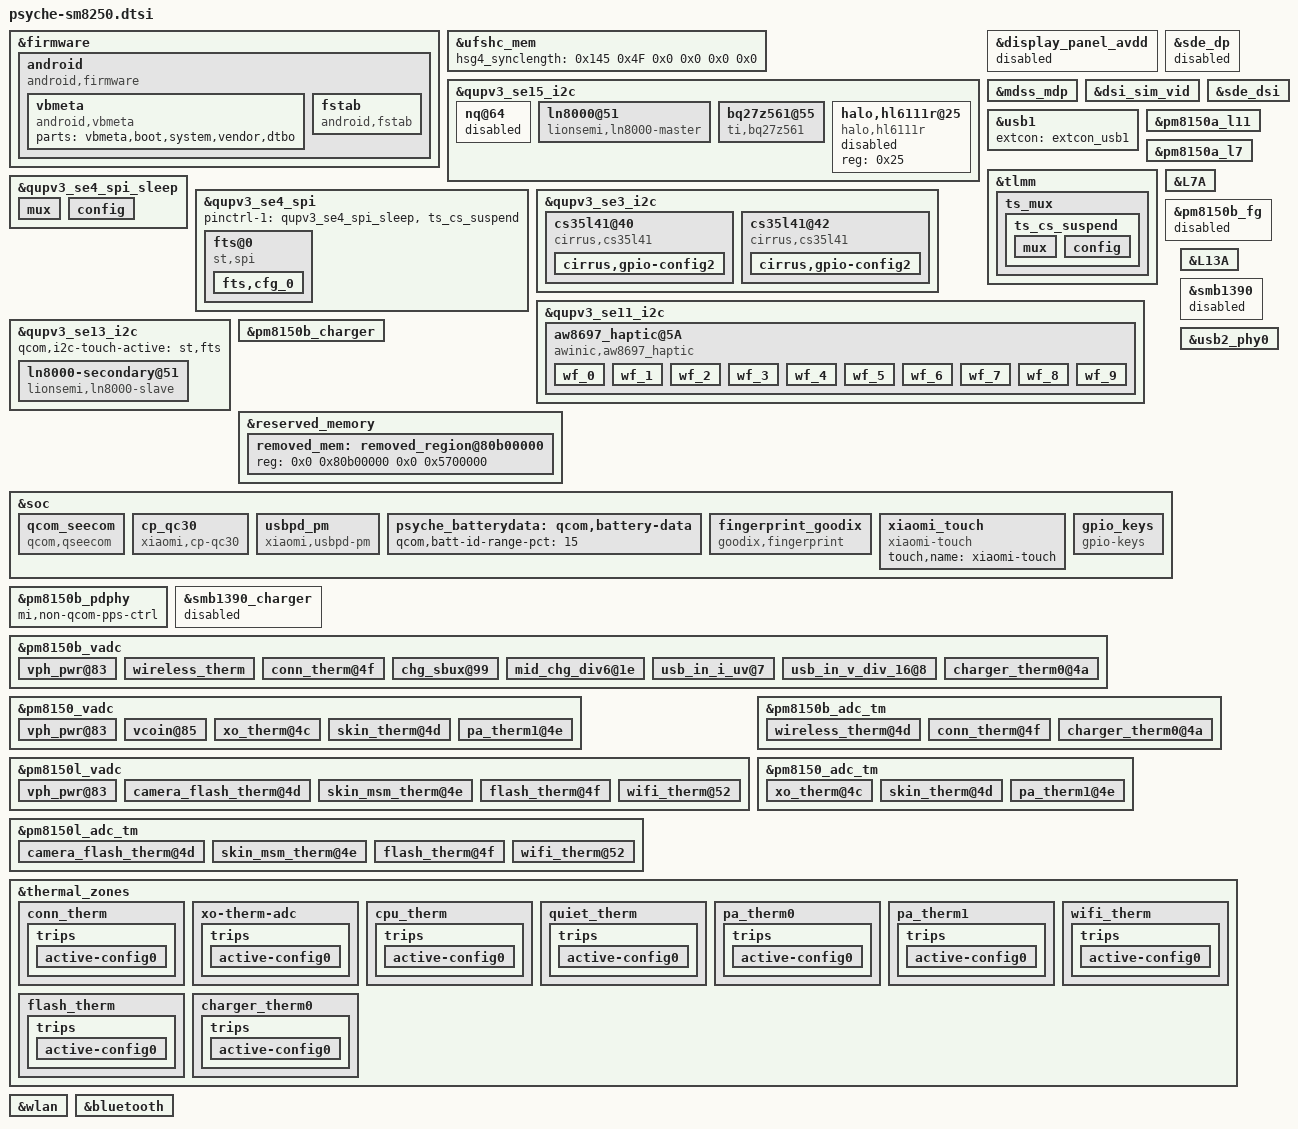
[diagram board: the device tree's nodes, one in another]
/*
this file is for attribution only of psyche
And public attribution of xiaomi platforms(like L3A and so and)
*/

#include "psyche-pinctrl.dtsi"
#include "xiaomi-sm8250-common.dtsi"
#include "psyche-audio-overlay.dtsi"

&firmware {
	android {
		compatible = "android,firmware";
		vbmeta {
			compatible = "android,vbmeta";
			parts = "vbmeta,boot,system,vendor,dtbo";
		};

		fstab {
			compatible = "android,fstab";
		};
	};
};
&ufshc_mem {
	hsg4_synclength = /bits/ 16 <0x145 0x4F
				     0x0 0x0
				     0x0 0x0>;
};

&qupv3_se15_i2c {
	status = "ok";
	nq@64 {
		status = "disabled";
	};
};

&display_panel_avdd {
	status = "disabled";
};

&sde_dp {
	status = "disabled";
};

&mdss_mdp {
	connectors = <&sde_wb &sde_dsi &sde_dsi1 &sde_rscc>;
};

&dsi_sim_vid {
	qcom,panel-supply-entries = <&dsi_panel_pwr_supply_vci>;
	qcom,platform-reset-gpio = <&tlmm 12 0>;
};

&usb1 {
        extcon = <&extcon_usb1>;
};

&sde_dsi {
	/delete-property/ vdd-supply;
	/delete-property/ avdd-supply;
	qcom,dsi-default-panel = <&dsi_sim_vid>;
	vci-supply = <&pm8150a_l11>;
};

&pm8150a_l11 {
	qcom,init-voltage = <3000000>;
	regulator-min-microvolt = <3000000>;
	regulator-max-microvolt = <3000000>;
};

&pm8150a_l7 {
	qcom,init-voltage = <3008000>;
	regulator-min-microvolt = <3008000>;
	regulator-max-microvolt = <3008000>;
	regulator-always-on;
};

&qupv3_se15_i2c {
	#address-cells = <1>;
	#size-cells = <0>;
	status = "ok";

	ln8000@51 {
		compatible = "lionsemi,ln8000-master";
		reg = <0x51>;
		/* bank <bit-idx> <flags: active-low> */
		//irq-gpios = <&tlmm 55 0x2002>;
		pinctrl-names = "bq2597x_master_irq";
		pinctrl-0 = <&bq2597x_master_int_default &bq2597x_master_int_suspend>;

		charger_name = "tertiary_chg";

		interrupt-parent = <&tlmm>;
		interrupts = <68 0x2002>;

		//interrupt-parent = <&tlmm>;
		//interrupts = <55 0x2002>;
		//pinctrl-names = "default";
		//pinctrl-0 = <&bq2597x_int_default &bq2597x_int_suspend>;
		//ln8000_charger,irq_index = <296>;

		ln8000_charger,standalone-mode-master;
		/* device configuration */
		ln8000_charger,bat-ovp-threshold = <4710>;
		ln8000_charger,bat-ovp-alarm-threshold = <4675>;
		ln8000_charger,bus-ovp-threshold = <13000>;
		ln8000_charger,bus-ovp-alarm-threshold = <11000>;
		ln8000_charger,bus-ocp-threshold = <3750>;
		ln8000_charger,bus-ocp-alarm-threshold = <3500>;
		ln8000_charger,ntc-alarm-cfg  = <226>;
		/* protection enable/disable flags
		 *   vbat-ovp-disable
		 *   vbat-reg-disable
		 *   iin-ocp-disable
		 *   iin-reg-disable
		 *   tbus-mon-disable
		 *   tbat-mon-disable
		 *   tdie-prot-disable
		 *   tdie-reg-disable
		 *   revcurr-prot-disable
		 */
		ln8000_charger,tdie-prot-disable;
		ln8000_charger,tbus-mon-disable;
		ln8000_charger,tbat-mon-disable;
		ln8000_charger,iin-ocp-disable;
		ln8000_charger,iin-reg-disable;
		ln8000_charger,tdie-reg-disable;
		ln8000_charger,vbat-reg-disable;
	};

	bq27z561@55 {
		compatible = "ti,bq27z561";
		reg = <0x55>;
		bq,ignore-digest-debug;
		bq,charge-full-design = <4500000>;
		bq,recharge-voltage   = <4430>;
		bq,shutdown-delay-enable;
		bq,soc_decimal_rate = <
			0  38
			10 35
			20 33
			30 33
			40 33
			50 33
			60 33
			70 30
			80 25
			90 20
			95 10 >;
		bq,cold_thermal_seq = <
			1      0  100 1700
			2  (-300)   0 1000 >;
	};

	halo,hl6111r@25 {
		compatible = "halo,hl6111r";
		reg = <0x25>;
		status = "disabled";
	};
};
&tlmm {
	ts_mux {
		ts_cs_suspend: ts_cs_suspend {
			mux {
				pins = "gpio11";
				function = "gpio";
			};

			config {
				pins = "gpio11";
				drive-strength = <6>;
				bias-pull-up;
			};
		};
	};
};

&qupv3_se4_spi_sleep {
	mux {
		pins = "gpio8", "gpio9", "gpio10";
		function = "gpio";
	};

	config {
		pins = "gpio8", "gpio9", "gpio10";
		drive-strength = <6>;
		bias-pull-down;
	};
};

&L7A {
	regulator-min-microvolt = <1800000>;
	regulator-max-microvolt = <1800000>;
	qcom,init-voltage = <1800000>;
};

&qupv3_se4_spi {
	status = "ok";
	pinctrl-1 = <&qupv3_se4_spi_sleep &ts_cs_suspend>;
	fts@0 {
		status = "ok";
		compatible = "st,spi";
		reg = <0x0>;
		interrupt-parent = <&tlmm>;
		interrupts = <39 0x2008>;
		pinctrl-names = "pmx_ts_active", "pmx_ts_suspend";
		pinctrl-0 = <&mi_ts_active>;
		pinctrl-1 = <&ts_int_suspend &ts_reset_suspend>;
		avdd-supply = <&L10C>;
		vdd-supply = <&L7A>;
		/*panel = <&dsi_k8_42_02_0a_dsc_cmd>;*/
		fts,pwr-reg-name = "avdd";
		fts,bus-reg-name = "vdd";
		fts,irq-gpio = <&tlmm 39 0x2008>;
		fts,irq-gpio-name = "fts_irq";
		fts,reset-gpio-enable;
		fts,reset-gpio = <&tlmm 33 0x00>;
		fts,reset-gpio-name = "fts_rst";
		fts,irq-flags = <0x2008>;
		fts,x-max = <10800>;
		fts,y-max = <24000>;
		fts,fod-lx = <4330>;
		fts,fod-ly = <20560>;
		fts,fod-x-size = <2140>;
		fts,fod-y-size = <2140>;
		fts,support-fod;
		fts,support-super-resolution = <1>;
		spi-max-frequency = <8000000>;
		fts,default-fw-name = "st_fts_l3a.ftb";
		fts,htp-fw-name = "st_fts_l3a_htp.ftb";
		fts,config-array-size = <1>;
		fts,touch-follow-performance-def = <3>;
		fts,touch-tap-sensitivity-def = <4>;
		fts,touch-aim-sensitivity-def = <3>;
		fts,touch-tap-stability-def = <3>;
		fts,cornerfilter-area-step1 = <100>;
		fts,cornerfilter-area-step2 = <170>;
		fts,cornerfilter-area-step3 = <250>;
		fts,touch-deadzone-filter-ver = <2 0 0 0 0 0 0 0
										2 1 0 0 0 0 0 0
										2 2 0   0 0    2399 0 0
										2 3 1079 0 1079 2399 0 0>;
		fts,touch-deadzone-filter-hor = <2 0 0 0 1079 0 0 0
										2 1 0    2399 1079 2399 0 0
										2 2 0    0    0    2399 0 0
										2 3 1079 0    1079 2399 0 0>;
		fts,touch-edgezone-filter-ver = <1 0 0 0 0 0 0 0
										1 1 0 0 0 0 0 0
										1 2 0    0 60   2339 0 0
										1 3 1019 0 1079 2339 0 0>;
		fts,touch-edgezone-filter-hor = <1 0 0 0 1079 60 0 0
										1 1 0    2339 1079 2399 0 0
										1 2 0    0    60   2399 0 0
										1 3 1019 0    1079 2399 0 0>;
		fts,touch-cornerzone-filter-ver = <0 0 0 0 0 0 0 0
										0 1 0 0 0 0 0 0
										0 2 0 2099 150 2399 0 0
										0 3 929 2099 1079 2399 0 0>;
		fts,touch-cornerzone-filter-hor1 = <0 0 0 0 170 170 0 0
										0 1 0 0 0 0 0 0
										0 2 0 2229 170 2399 0 0
										0 3 0 0 0 0 0 0>;
		fts,touch-cornerzone-filter-hor2 = <0 0 0 0 0 0 0 0
										0 1 909 0    1079 170  0 0
										0 2 0 0 0 0 0 0
										0 3 909 2229 1079 2399 0 0>;
		fts,touch-follow-performance = <10 15 1
										8 15 1
										6 15 1
										4 15 1
										2 15 1>;
		fts,touch-tap-sensitivity = <160 150 140 120 100>;
		fts,touch-aim-sensitivity = <10 8 6 5 3>;
		fts,touch-tap-stability = <8 12 15 18 25>;
		fts,touch-expert-array = <6 15 1 120 6 15
								  2 15 1 120 5 15
								  4 15 1 120 3 15>;
		fts,cfg_0 {
			fts,tp-vendor = <0x38>;
			fts,fw-name = "st_fts_l3a.ftb";
			fts,limit-name = "stm_fts_production_limits.csv";
		};
	};
};

&qupv3_se3_i2c {
	status = "ok";

		/* Speaker */
	cs35l41@40 {
		#sound-dai-cells = <1>;
		compatible = "cirrus,cs35l41";
		reset-gpios = <&tlmm 114 0>;
		reg = <0x40>;
		pinctrl-names = "cs35l41_irq_speaker";
		pinctrl-0 = <&cs35l41_int_speaker>;
		interrupt-parent = <&tlmm>;
		interrupts = <113 8>;
		cirrus,temp-warn_threshold = <3>;
		cirrus,boost-peak-milliamp = <4000>;
		cirrus,boost-ind-nanohenry = <1000>;
		cirrus,boost-cap-microfarad = <15>;
		cirrus,asp-sdout-hiz = <1>;
		cirrus,right-channel-amp;
		cirrus,gpio-config2 {
			cirrus,gpio-src-select = <0x4>;
			cirrus,gpio-output-enable;
		};

	};
	/* Receiver */
	cs35l41@42 {
		#sound-dai-cells = <1>;
		compatible = "cirrus,cs35l41";
		reset-gpios = <&tlmm 114 0>;
		reg = <0x42>;
		pinctrl-names = "cs35l41_irq_speaker_rcv";
		pinctrl-0 = <&cs35l41_int_speaker_rcv>;
		interrupt-parent = <&tlmm>;
		interrupts = <15 8>;
		cirrus,temp-warn_threshold = <3>;
		cirrus,boost-peak-milliamp = <4000>;
		cirrus,boost-ind-nanohenry = <1000>;
		cirrus,boost-cap-microfarad = <15>;
		//cirrus,right-channel-amp;
		cirrus,asp-sdout-hiz = <1>;
		sound-name-prefix = "RCV";
		cirrus,gpio-config2 {
			cirrus,gpio-src-select = <0x4>;
			cirrus,gpio-output-enable;
		};

	};

};

&qupv3_se11_i2c {
	status = "ok";
	aw8697_haptic@5A {
		compatible = "awinic,aw8697_haptic";
		vib_bst_vol_default = < 0x0c >;
		vib_bst_vol_ram = < 0x10 >;
		vib_bst_vol_rtp = < 0x10 >;
		status = "ok";
	};
};

&qupv3_se13_i2c {
	#address-cells = <1>;
	#size-cells = <0>;
	qcom,i2c-touch-active = "st,fts";
	status = "ok";

	ln8000-secondary@51 {
		compatible = "lionsemi,ln8000-slave";
		reg = <0x51>;
		//pinctrl-names = "bq2597x_slave_irq";
		//pinctrl-0 = <&bq2597x_slave_int_default &bq2597x_slave_int_suspend>;

		charger_name = "quaternary_chg";
		/* bank <bit-idx> <flags: active-low> */
		//irq-gpios = <&tlmm 55 0x2002>;
		interrupt-parent = <&tlmm>;
		interrupts = <64 0x2002>;

		//interrupt-parent = <&tlmm>;
		//interrupts = <55 0x2002>;
		//pinctrl-names = "default";
		//pinctrl-0 = <&bq2597x_int_default &bq2597x_int_suspend>;
		//ln8000_charger,irq_index = <296>;

		ln8000_charger,standalone-mode-slave;
		/* device configuration */
		ln8000_charger,bat-ovp-threshold = <4710>;
		ln8000_charger,bat-ovp-alarm-threshold = <4675>;
		ln8000_charger,bus-ovp-threshold = <13000>;
		ln8000_charger,bus-ovp-alarm-threshold = <11000>;
		ln8000_charger,bus-ocp-threshold = <3750>;
		ln8000_charger,bus-ocp-alarm-threshold = <3500>;
		ln8000_charger,ntc-alarm-cfg  = <226>;
		/* protection enable/disable flags
		 *   vbat-ovp-disable
		 *   vbat-reg-disable
		 *   iin-ocp-disable
		 *   iin-reg-disable
		 *   tbus-mon-disable
		 *   tbat-mon-disable
		 *   tdie-prot-disable
		 *   tdie-reg-disable
		 *   revcurr-prot-disable
		 */
		ln8000_charger,tdie-prot-disable;
		ln8000_charger,tbus-mon-disable;
		ln8000_charger,tbat-mon-disable;
		ln8000_charger,iin-ocp-disable;
		ln8000_charger,iin-reg-disable;
		ln8000_charger,tdie-reg-disable;
		ln8000_charger,vbat-reg-disable;
	};
};

&pm8150b_charger {
	status = "ok";
	qcom,sec-charger-config = <0>;
	qcom,usb-icl-ua = <6200000>;
	qcom,fcc-max-ua = <12300000>;
	qcom,fv-max-uv = <4540000>;
	qcom,non-fcc-fv-max-uv = <4480000>;
	qcom,dc-icl-ua = <1000000>;
	qcom,auto-recharge-vbat-mv = <4430000>;
	qcom,chg-term-src = <1>;
	qcom,chg-term-current-ma = <(-200)>;
	qcom,step-charging-enable;
	qcom,sw-jeita-enable;
	qcom,chg-warm-th= <480>;
	qcom,chg-cool-th= <150>;
	//qcom,suspend-input-on-debug-batt;
	pinctrl-names = "default", "smb5_active", "smb5_suspend";
	pinctrl-0 = <&vbus_disable_suspend>;
	qcom,usbpd-phandle = <&pm8150b_pdphy>;
	qcom,battery-data = <&psyche_batterydata>;
	//mi,fcc-batt-unverify-ua = <2000000>;
	mi,support-ffc;
	qcom,lpd-disable;
	mi,use-bq-pump;
	qcom,support-ext-fg;
	mi,support-qc3p5-without-smb;
	qcom,disable-suspend-on-collapse;
	qcom,distinguish-qc-class-ab;
	qcom,support-conn-therm;
	vbus-disable-gpio = <&tlmm 25 GPIO_ACTIVE_HIGH>;
	pinctrl-names = "default", "vbus_disable_active", "vbus_disable_suspend";
	pinctrl-0 = <&vbus_disable_suspend>;
	pinctrl-1 = <&vbus_disable_active>;
	pinctrl-2 = <&vbus_disable_suspend>;

	io-channels = <&pm8150b_vadc ADC_USB_IN_V_16>,
			<&pm8150b_vadc ADC_MID_CHG_DIV6>,
			<&pm8150b_vadc ADC_USB_IN_I>,
			<&pm8150b_vadc ADC_SBUx>,
			<&pm8150b_vadc ADC_VPH_PWR>,
			<&pm8150b_vadc ADC_AMUX_THM3_PU2>,
			<&pm8150b_vadc ADC_CHG_TEMP>;
	io-channel-names = "usb_in_voltage",
			"mid_voltage",
			"usb_in_current",
			"sbux_res",
			"vph_voltage",
			"conn_temp",
			"chg_temp";
	qcom,thermal-mitigation = <3000000 2800000 2600000 2400000 2200000 2100000 2000000
				   1800000 1600000 1500000 1400000 1200000 1000000 900000
				   800000 500000>;
	qcom,thermal-mitigation-icl
				= <2800000 2700000 2600000 2400000 2200000 2100000 2000000
				   1800000 1600000 1500000 1400000 1300000 1200000 1100000
				   950000 750000>;
	qcom,thermal-mitigation-dcp
				= <1800000 1800000 1800000 1800000 1800000 1800000 1800000
				   1800000 1800000 1700000 1600000 1400000 1200000 1100000
				   1100000 1000000>;
	qcom,thermal-mitigation-qc2
				= <1500000 1500000 1500000 1500000 1450000 1400000 1350000
				   1300000 1150000 1100000 1000000 900000 850000 750000
				   650000 500000>;
	qcom,thermal-fcc-qc3-normal
				= <3200000 3000000 2800000 2600000 2500000 2400000 2300000
				   2200000 2100000 1800000 1600000 1400000 1200000 1000000
				   750000 750000>;
	qcom,thermal-fcc-qc3-cp
				= <4800000 4600000 4400000 4200000 4000000 3800000 3600000
				   3400000 3000000 2600000 2400000 2200000 2000000 1300000
				   1000000 700000>;
	qcom,thermal-fcc-qc3-classb-cp
				= <5100000 4700000 4300000 4000000 3600000 3500000 3400000
				   3400000 3400000 3200000 2500000 2200000 2000000 1300000
				   1000000 700000>;
	qcom,thermal-mitigation-pd-base
				= <3000000 2800000 2600000 2400000 2200000 2000000 1800000
				   1600000 1600000 1400000 1200000 1100000 1050000 1000000
				   950000 500000>;
	qcom,thermal-fcc-pps-bq
				= <12300000 10000000 8800000 8000000 6600000 6000000 5600000
				   5000000 4400000 3500000 3000000 2400000 2000000 1500000
				   1000000 300000>;
};

&pm8150b_fg {
	status = "disabled";
};

&reserved_memory {
	removed_mem: removed_region@80b00000 {
		reg = <0x0 0x80b00000 0x0 0x5700000>;
	};
};

&soc {
	qcom_seecom {
		compatible = "qcom,qseecom";
		reg = <0x82400000 0x3E00000>;
		reg-names = "secapp-region";
		memory-region = <&qseecom_mem>;
		qcom,hlos-num-ce-hw-instances = <1>;
		qcom,hlos-ce-hw-instance = <0>;
		qcom,qsee-ce-hw-instance = <0>;
		qcom,disk-encrypt-pipe-pair = <2>;
		qcom,support-fde;
		qcom,no-clock-support;
		qcom,fde-key-size;
		qcom,appsbl-qseecom-support;
		qcom,commonlib64-loaded-by-uefi;
		qcom,qsee-reentrancy-support = <2>;
	};

	cp_qc30 {
		compatible = "xiaomi,cp-qc30";
		status = "ok";
		mi,qc3-bat-volt-max = <4480>;
		mi,qc3-bat-curr-max = <3600>;
		mi,qc3-bus-volt-max = <12000>;
		mi,qc3-bus-curr-max = <2100>;
		mi,qc3-battery-warm-th = <480>;
		mi,cp-sec-enable;
		mi,support-qc3p5-without-smb;
	};

	usbpd_pm {
		compatible = "xiaomi,usbpd-pm";
		status = "ok";
		mi,pd-bat-volt-max = <4540>;
		mi,pd-bat-curr-max = <12300>;
		mi,pd-bus-volt-max = <12000>;
		mi,pd-bus-curr-max = <6200>;
		mi,pd-non-ffc-bat-volt-max = <4480>;
		mi,pd-bus-curr-compensate  = <0>;
		mi,step-charge-high-vol-curr-max = <4400>;
		mi,cell-vol-high-threshold-mv = <4510>;
		mi,cell-vol-max-threshold-mv = <4540>;
		mi,pd-battery-warm-th = <480>;
		mi,cp-sec-enable;
	};

/*
	maxim_ds28e16: maxim_ds28e16 {
		compatible = "maxim,ds28e16";
		label = "max_ds28e16";
		maxim,version = <1>;
		status = "ok";
	};
*/
	psyche_batterydata: qcom,battery-data {
		qcom,batt-id-range-pct = <15>;
		#include "jeita-step-cfg-psyche.dtsi"
	};

	fingerprint_goodix {
		status = "ok";
		compatible = "goodix,fingerprint";
		goodix,gpio-reset = <&tlmm 24 0x0>;
		goodix,gpio-irq = <&tlmm 23 0x0>;
                l13a_vdd-supply = <&L13A>;
		//fp-gpio-pwr = <&tlmm 10 0x0>;
	};
/*
	fingerprint_3P0_VREG: fingerprint_3P0_VREG {
		compatible = "regulator-fixed";
		regulator-name = "fingerprint_3P0_VREG";
		startup-delay-us = <4000>;
		enable-active-high;
		gpio = <&tlmm 10 0>;
		regulator-always-on;
	};
*/

	xiaomi_touch {
		compatible = "xiaomi-touch";
		status = "ok";
		touch,name = "xiaomi-touch";
	};

	gpio_keys {
		compatible = "gpio-keys";
		label = "gpio-keys";

		pinctrl-names = "default";
		pinctrl-0 = <&key_vol_up_default>;
	};
};

&L13A {
        regulator-min-microvolt = <3204000>;
        regulator-max-microvolt = <3204000>;
        qcom,init-voltage = <3204000>;
};

&pm8150b_pdphy {
	mi,non-qcom-pps-ctrl;
};

&smb1390 {
	status = "disabled";
};

&smb1390_charger {
	status = "disabled";
};

&usb2_phy0 {
	qcom,param-override-seq =
		<0xE7 0x6C
		 0xC9 0x70
		 0x07 0x74>;
	qcom,global-param-override-seq =
		<0xE5 0x6C
		 0x79 0x70
		 0x2c 0x74>;
};

&pm8150b_vadc {
	#address-cells = <1>;
	#size-cells = <0>;

	vph_pwr@83 {
		reg = <ADC_VPH_PWR>;
		label = "vph_pwr";
		qcom,pre-scaling = <1 3>;
	};

	wireless_therm {
		reg = <ADC_AMUX_THM1_PU2>;
		label = "wireless_therm";
		qcom,ratiometric;
		qcom,hw-settle-time = <200>;
		qcom,pre-scaling = <1 1>;
	};

	conn_therm@4f {
		reg = <ADC_AMUX_THM3_PU2>;
		label = "conn_therm";
		qcom,ratiometric;
		qcom,hw-settle-time = <200>;
		qcom,pre-scaling = <1 1>;
	};

	chg_sbux@99 {
		reg = <ADC_SBUx>;
		label = "chg_sbux";
		qcom,pre-scaling = <1 3>;
	};

	mid_chg_div6@1e {
		reg = <ADC_MID_CHG_DIV6>;
		label = "chg_mid";
		qcom,pre-scaling = <1 6>;
	};

	usb_in_i_uv@7 {
		reg = <ADC_USB_IN_I>;
		label = "usb_in_i_uv";
		qcom,pre-scaling = <1 1>;
	};

	usb_in_v_div_16@8 {
		reg = <ADC_USB_IN_V_16>;
		label = "usb_in_v_div_16";
		qcom,pre-scaling = <1 16>;
	};

	charger_therm0@4a {
		reg = <ADC_BAT_THERM_PU2>;
		label = "charger_therm0";
		qcom,ratiometric;
		qcom,hw-settle-time = <200>;
		qcom,pre-scaling = <1 1>;
	};
};

&pm8150_vadc {
	#address-cells = <1>;
	#size-cells = <0>;

	vph_pwr@83 {
		reg = <ADC_VPH_PWR>;
		label = "vph_pwr";
		qcom,pre-scaling = <1 3>;
	};

	vcoin@85 {
		reg = <ADC_VCOIN>;
		label = "vcoin";
		qcom,pre-scaling = <1 3>;
	};

	xo_therm@4c {
		reg = <ADC_XO_THERM_PU2>;
		label = "xo_therm";
		qcom,ratiometric;
		qcom,hw-settle-time = <200>;
		qcom,pre-scaling = <1 1>;
	};

	skin_therm@4d {
		reg = <ADC_AMUX_THM1_PU2>;
		label = "skin_therm";
		qcom,ratiometric;
		qcom,hw-settle-time = <200>;
		qcom,pre-scaling = <1 1>;
	};

	pa_therm1@4e {
		reg = <ADC_AMUX_THM2_PU2>;
		label = "pa_therm1";
		qcom,ratiometric;
		qcom,hw-settle-time = <200>;
		qcom,pre-scaling = <1 1>;
	};
};

&pm8150l_vadc {
	#address-cells = <1>;
	#size-cells = <0>;

	vph_pwr@83 {
		reg = <ADC_VPH_PWR>;
		label = "vph_pwr";
		qcom,pre-scaling = <1 3>;
	};

	camera_flash_therm@4d {
		reg = <ADC_AMUX_THM1_PU2>;
		label = "camera_flash_therm";
		qcom,ratiometric;
		qcom,hw-settle-time = <200>;
		qcom,pre-scaling = <1 1>;
	};

	skin_msm_therm@4e {
		reg = <ADC_AMUX_THM2_PU2>;
		label = "skin_msm_therm";
		qcom,ratiometric;
		qcom,hw-settle-time = <200>;
		qcom,pre-scaling = <1 1>;
	};

	flash_therm@4f {
		reg = <ADC_AMUX_THM3_PU2>;
		label = "flash_therm";
		qcom,ratiometric;
		qcom,hw-settle-time = <200>;
		qcom,pre-scaling = <1 1>;
	};

	wifi_therm@52 {
		reg = <ADC_GPIO1_PU2>;
		label = "wifi_therm";
		qcom,ratiometric;
		qcom,hw-settle-time = <200>;
		qcom,pre-scaling = <1 1>;
	};
};

&pm8150b_adc_tm {
	#address-cells = <1>;
	#size-cells = <0>;

	io-channels = <&pm8150b_vadc ADC_AMUX_THM1_PU2>,
			<&pm8150b_vadc ADC_AMUX_THM3_PU2>,
			<&pm8150b_vadc ADC_BAT_THERM_PU2>;

	wireless_therm@4d {
		reg = <ADC_AMUX_THM1_PU2>;
		qcom,ratiometric;
		qcom,hw-settle-time = <200>;
	};

	conn_therm@4f {
		reg = <ADC_AMUX_THM3_PU2>;
		qcom,ratiometric;
		qcom,hw-settle-time = <200>;
	};

	charger_therm0@4a {
		reg = <ADC_BAT_THERM_PU2>;
		qcom,ratiometric;
		qcom,hw-settle-time = <200>;
	};
};

&pm8150_adc_tm {
	#address-cells = <1>;
	#size-cells = <0>;

	io-channels = <&pm8150_vadc ADC_XO_THERM_PU2>,
			<&pm8150_vadc ADC_AMUX_THM1_PU2>,
			<&pm8150_vadc ADC_AMUX_THM2_PU2>;

	xo_therm@4c {
		reg = <ADC_XO_THERM_PU2>;
		qcom,ratiometric;
		qcom,hw-settle-time = <200>;
	};

	skin_therm@4d {
		reg = <ADC_AMUX_THM1_PU2>;
		qcom,ratiometric;
		qcom,hw-settle-time = <200>;
	};

	pa_therm1@4e {
		reg = <ADC_AMUX_THM2_PU2>;
		qcom,ratiometric;
		qcom,hw-settle-time = <200>;
	};
};

&pm8150l_adc_tm {
	#address-cells = <1>;
	#size-cells = <0>;

	io-channels = <&pm8150l_vadc ADC_AMUX_THM1_PU2>,
			<&pm8150l_vadc ADC_AMUX_THM2_PU2>,
			<&pm8150l_vadc ADC_AMUX_THM3_PU2>,
			<&pm8150l_vadc ADC_GPIO1_PU2>;

	camera_flash_therm@4d {
		reg = <ADC_AMUX_THM1_PU2>;
		qcom,ratiometric;
		qcom,hw-settle-time = <200>;
	};

	skin_msm_therm@4e {
		reg = <ADC_AMUX_THM2_PU2>;
		qcom,ratiometric;
		qcom,hw-settle-time = <200>;
	};

	flash_therm@4f {
		reg = <ADC_AMUX_THM3_PU2>;
		qcom,ratiometric;
		qcom,hw-settle-time = <200>;
	};

	wifi_therm@52 {
		reg = <ADC_GPIO1_PU2>;
		qcom,ratiometric;
		qcom,hw-settle-time = <200>;
	};
};

&thermal_zones {
/*	wireless_therm {//place close to wireless charge RX
		polling-delay-passive = <0>;
		polling-delay = <0>;
		thermal-governor = "user_space";
		thermal-sensors = <&pm8150b_adc_tm ADC_AMUX_THM1_PU2>;
		trips {
			active-config0 {
				temperature = <125000>;
				hysteresis = <1000>;
				type = "passive";
			};
		};
	};
*/

	conn_therm {//place close to type-c connector
		polling-delay-passive = <0>;
		polling-delay = <0>;
		thermal-governor = "user_space";
		thermal-sensors = <&pm8150b_adc_tm ADC_AMUX_THM3_PU2>;
		wake-capable-sensor;
		trips {
			active-config0 {
				temperature = <125000>;
				hysteresis = <1000>;
				type = "passive";
			};
		};
	};

	xo-therm-adc {
		polling-delay-passive = <0>;
		polling-delay = <0>;
		thermal-governor = "user_space";
		thermal-sensors = <&pm8150_adc_tm ADC_XO_THERM_PU2>;
		wake-capable-sensor;
		trips {
			active-config0 {
				temperature = <125000>;
				hysteresis = <1000>;
				type = "passive";
			};
		};
	};

	cpu_therm {//place close to sm8250
		polling-delay-passive = <0>;
		polling-delay = <0>;
		thermal-governor = "user_space";
		thermal-sensors = <&pm8150_adc_tm ADC_AMUX_THM1_PU2>;
		wake-capable-sensor;
		trips {
			active-config0 {
				temperature = <125000>;
				hysteresis = <1000>;
				type = "passive";
			};
		};
	};

	quiet_therm {//place close to a cool place
		polling-delay-passive = <0>;
		polling-delay = <0>;
		thermal-governor = "user_space";
		thermal-sensors = <&pm8150_adc_tm ADC_AMUX_THM2_PU2>;
		wake-capable-sensor;
		trips {
			active-config0 {
				temperature = <125000>;
				hysteresis = <1000>;
				type = "passive";
			};
		};
	};

	pa_therm0 {//place close to pa0
		polling-delay-passive = <0>;
		polling-delay = <0>;
		thermal-governor = "user_space";
		thermal-sensors = <&pm8150l_adc_tm ADC_AMUX_THM1_PU2>;
		wake-capable-sensor;
		trips {
			active-config0 {
				temperature = <125000>;
				hysteresis = <1000>;
				type = "passive";
			};
		};
	};

	pa_therm1 {//place close to pa1
		polling-delay-passive = <0>;
		polling-delay = <0>;
		thermal-governor = "user_space";
		thermal-sensors = <&pm8150l_adc_tm ADC_AMUX_THM2_PU2>;
		wake-capable-sensor;
		trips {
			active-config0 {
				temperature = <125000>;
				hysteresis = <1000>;
				type = "passive";
			};
		};
	};

	wifi_therm {//place close to wifi
		polling-delay-passive = <0>;
		polling-delay = <0>;
		thermal-governor = "user_space";
		thermal-sensors = <&pm8150l_adc_tm ADC_GPIO1_PU2>;
		wake-capable-sensor;
		trips {
			active-config0 {
				temperature = <125000>;
				hysteresis = <1000>;
				type = "passive";
			};
		};
	};

	flash_therm {//place close to flash fpc
		polling-delay-passive = <0>;
		polling-delay = <0>;
		thermal-governor = "user_space";
		thermal-sensors = <&pm8150l_adc_tm ADC_AMUX_THM3_PU2>;
		wake-capable-sensor;
		trips {
			active-config0 {
				temperature = <125000>;
				hysteresis = <1000>;
				type = "passive";
			};
		};
	};

	charger_therm0 {//place close to charge IC
		polling-delay-passive = <0>;
		polling-delay = <0>;
		thermal-governor = "user_space";
		thermal-sensors = <&pm8150b_adc_tm ADC_BAT_THERM_PU2>;
		wake-capable-sensor;
		trips {
			active-config0 {
				temperature = <125000>;
				hysteresis = <1000>;
				type = "passive";
			};
		};
	};

/*	cam_therm1 {//place close to rear camera
		polling-delay-passive = <0>;
		polling-delay = <0>;
		thermal-governor = "user_space";
		thermal-sensors = <&pm8150l_adc_tm ADC_AMUX_THM1_PU2>;
		wake-capable-sensor;
		trips {
			active-config0 {
				temperature = <125000>;
				hysteresis = <1000>;
				type = "passive";
			};
		};
	};

	xo_therm {//place close to sm8250 hot place
		polling-delay-passive = <0>;
		polling-delay = <0>;
		thermal-governor = "user_space";
		thermal-sensors = <&pm8150l_adc_tm ADC_AMUX_THM2_PU2>;
		wake-capable-sensor;
		trips {
			active-config0 {
				temperature = <125000>;
				hysteresis = <1000>;
				type = "passive";
			};
		};
	};

	mmw-pa2-usr {
		polling-delay-passive = <0>;
		polling-delay = <0>;
		thermal-governor = "user_space";
		thermal-sensors = <&pm8150l_adc_tm ADC_AMUX_THM3_PU2>;
		wake-capable-sensor;
		trips {
			active-config0 {
				temperature = <125000>;
				hysteresis = <1000>;
				type = "passive";
			};
		};
	};
*/
};

&wlan {
       vdd-wlan-dig-supply = <&pm8150_s6>;
       qcom,vdd-wlan-dig-config = <950000 950000 0 0 1>;
};

&bluetooth {
        qca,bt-vdd-dig-supply = <&pm8150_s6>;
        qca,bt-vdd-dig-voltage-level = <950000 950000>;
};

&qupv3_se11_i2c {
	status = "ok";
	aw8697_haptic@5A {
		compatible = "awinic,aw8697_haptic";
		reg = <0x5A>;
		reset-gpio = <&tlmm 130 0>;
		irq-gpio = <&tlmm 129 0>;
		vib_mode = < 0 >;   /*mode:   RAM mode->0; CONT mode -> 1*/
		vib_f0_pre = < 1700 >;
		vib_f0_cali_percen = < 7 >;
		vib_cont_drv_lev = < 38 >;
		vib_cont_drv_lvl_ov = < 50 >;
		vib_cont_td = < 0x009A >;
		vib_cont_zc_thr = < 0x0FF1 >;  /*hq 0x08F8 */
		vib_cont_num_brk = < 3 >;
		vib_f0_coeff = < 260 >; /*Don't modify it    2.604167*/
		vib_f0_trace_parameter = < 0x05 0x03 0x02 0x0f >;
		vib_bemf_config = < 0x10 0x08 0x03 0xf8 >;
		vib_sw_brake = < 0x2c >;
		vib_tset = < 0x12 >;
		vib_r_spare = < 0x68 >;
		vib_bstdbg = < 0x30 0xeb 0xd4 0 0 0 >;
		vib_effect_id_boundary = < 10 >;
		vib_effect_max = < 193 >;   /*vib_effect_max must bigger than vib_effect_id*/
		vib_trig_config = < 0 1 0 1 2
						0 1 0 1 2
						0 1 0 1 2 >;
		vib_bst_vol_default = < 0x10 >;
		vib_bst_vol_ram = < 0x10 >;
		vib_bst_vol_rtp = < 0x10 >;
		vib_rtp_time = < 20 20 20 20 20 20 20 20 20000 15000
				 15000 20000 25000 15000 30000 25000 20000 20000 20000 20000
				 20000 20000 20000 20000 20000 20000 20000 20000 20000 20000
				 20000 20000 20000 20000 20000 20000 20000 20000 20000 20000
				 20000 20000 20000 20000 20000 20000 20000 20000 20000 20000
				 20000 20000 20000 20000 20000 20000 20000 20000 20000 20000
				 20000 20000 20000 20000 20000 20000 20000 20000 20000 20000
				 20000 20000 20000 20000 20000 20000 20000 20000 20000 20000
				 20000 20000 20000 20000 20000 20000 20000 20000 20000 20000
				 20000 20000 20000 20000 20000 20000 20000 20000 20000 20000
				 20000 20000 20000 20000 20000 20000 20000 20000 20000 20000
				 20000 20000 20000 20000 20000 20000 20000 20000 20000 20000
				 20000 20000 20000 20000 20000 20000 20000 20000 20000 20000
				 20000 20000 20000 20000 20000 20000 20000 20000 20000 20000
				 20000 20000 20000 20000 20000 20000 20000 20000 20000 20000
				 20000 20000 20000 20000 20000 20000 20000 20000 20000 20000
				 20000 20000 20000 20000 20000 20000 20000 20000 20000 20000
				 20000 20000 20000 20000 20000 >;
		pinctrl-names = "aw8697_reset_reset","aw8697_reset_active","aw8697_interrupt_active";
		pinctrl-0 = <&aw8697_gpio_reset>;
		pinctrl-1 = <&aw8697_gpio_reset_output_high>;
		pinctrl-2 = <&aw8697_gpio_int>;
		status = "ok";
		wf_0 {
			/*CLICK*/
			qcom,effect-id = <0>;
			qcom,wf-vmax-mv = <3600>;
			qcom,wf-pattern = [3e 3e];
			qcom,wf-brake-pattern = [02 01 00 00];
			qcom,wf-play-rate-us = <20000>;
		};
		wf_1 {
			/*DOUBLE CLICK*/
			qcom,effect-id = <1>;
			qcom,wf-vmax-mv = <3600>;
			qcom,wf-pattern = [7e 3e];
			qcom,wf-brake-pattern = [03 01 00 00];
			qcom,wf-play-rate-us = <20000>;
		};
		wf_2 {
			/*TICK*/
			qcom,effect-id = <2>;
			qcom,wf-vmax-mv = <3600>;
			qcom,wf-pattern = [7e 3e];
			qcom,wf-brake-pattern = [02 01 00 00];
			qcom,wf-play-rate-us = <20000>;
		};
		wf_3 {
			/*THUD*/
			qcom,effect-id = <3>;
			qcom,wf-vmax-mv = <3600>;
			qcom,wf-pattern = [3e 3e];
			qcom,wf-brake-pattern = [02 01 00 00];
			qcom,wf-play-rate-us = <20000>;
		};
		wf_4 {
			/*POP*/
			qcom,effect-id = <4>;
			qcom,wf-vmax-mv = <3600>;
			qcom,wf-pattern = [3e 3e];
			qcom,wf-brake-pattern = [02 01 00 00];
			qcom,wf-play-rate-us = <28000>;
		};
		wf_5 {
			/*HEAVY CLICK*/
			qcom,effect-id = <5>;
			qcom,wf-vmax-mv = <3600>;
			qcom,wf-pattern = [7e 7e 7e];
			qcom,wf-brake-pattern = [03 03 01 00];
			qcom,wf-play-rate-us = <20000>;
		};
		wf_6 {
			/*id 6*/
			qcom,effect-id = <6>;
			qcom,wf-vmax-mv = <3600>;
			qcom,wf-pattern = [3e 3e];
			qcom,wf-brake-pattern = [02 01 00 00];
			qcom,wf-play-rate-us = <20000>;
		};
		wf_7 {
			/*id 7*/
			qcom,effect-id = <7>;
			qcom,wf-vmax-mv = <3600>;
			qcom,wf-pattern = [3e 3e];
			qcom,wf-brake-pattern = [02 01 00 00];
			qcom,wf-play-rate-us = <20000>;
		};
		wf_8 {
			/*id 8*/
			qcom,effect-id = <8>;
			qcom,wf-vmax-mv = <3600>;
			qcom,wf-pattern = [3e 3e];
			qcom,wf-brake-pattern = [02 01 00 00];
			qcom,wf-play-rate-us = <20000>;
		};
		wf_9 {
			/*id 9*/
			qcom,effect-id = <9>;
			qcom,wf-vmax-mv = <3600>;
			qcom,wf-pattern = [3e 3e];
			qcom,wf-brake-pattern = [02 01 00 00];
			qcom,wf-play-rate-us = <20000>;
		};
	};
};
